# MCXC444 register map
Vendor: NXP Semiconductors; Series: MCX; File version: 1.6
CPU: CM0PLUS r0p0, little endian, no MPU, no FPU, VTOR, 2 interrupt priority bits
Registers are 32-bit, read-write, reset 0x0 unless marked. A register's access mark holds for its fields unless they carry their own. Offsets are from the block's base; [hi:lo] are bit positions.

## SystemControl — System Control Block
Base 0xE000E000; register names take the prefix SCB_
0x08 ACTLR ro — Auxiliary Control Register,
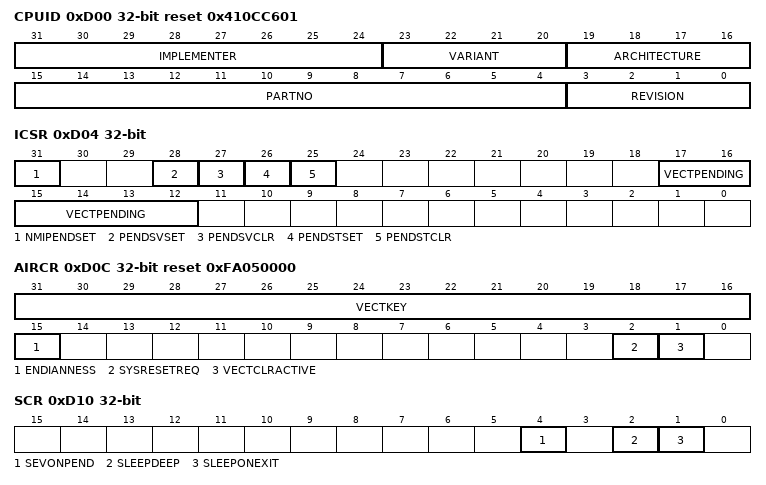
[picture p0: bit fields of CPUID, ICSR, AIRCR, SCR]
0xD00 CPUID ro reset 0x410CC601 — CPUID Base Register
  [31:24] IMPLEMENTER — Implementer code
  [23:20] VARIANT — Major revision number n in the npm revision status
  [19:16] ARCHITECTURE — Indicates the architecture
  [15:4] PARTNO — Indicates part number
  [3:0] REVISION — Minor revision number m in the rnpm revision status
0xD04 ICSR — Interrupt Control and State Register
  [31] NMIPENDSET — NMI set-pending bit
    0=b0 (write: no effect; read: NMI exception is not pending); 1=b1 (write: changes NMI exception state to pending; read: NMI exception is pending)
  [28] PENDSVSET — PendSV set-pending bit
    0=b0 (write: no effect; read: PendSV exception is not pending); 1=b1 (write: changes PendSV exception state to pending; read: PendSV exception is pending)
  [27] PENDSVCLR wo — PendSV clear-pending bit
    0=b0 (no effect); 1=b1 (removes the pending state from the PendSV exception)
  [26] PENDSTSET — SysTick exception set-pending bit
    0=b0 (write: no effect; read: SysTick exception is not pending); 1=b1 (write: changes SysTick exception state to pending; read: SysTick exception is pending)
  [25] PENDSTCLR wo — SysTick exception clear-pending bit
    0=b0 (no effect); 1=b1 (removes the pending state from the SysTick exception)
  [17:12] VECTPENDING ro — Exception number of the highest priority pending enabled exception
0xD08 VTOR — Vector Table Offset Register
  [31:7] TBLOFF — Vector table base offset
0xD0C AIRCR reset 0xFA050000 — Application Interrupt and Reset Control Register
  [31:16] VECTKEY — Register key
  [15] ENDIANNESS ro — Data endianness bit
    0=b0 (Little-endian); 1=b1 (Big-endian)
  [2] SYSRESETREQ wo — System reset request
    0=b0 (no system reset request); 1=b1 (asserts a signal to the outer system that requests a reset)
  [1] VECTCLRACTIVE wo — Reserved for Debug use
0xD10 SCR — System Control Register
  [4] SEVONPEND — Send Event on Pending bit
    0=b0 (only enabled interrupts or events can wakeup the processor, disabled interrupts are excluded); 1=b1 (enabled events and all interrupts, including disabled interrupts, can wakeup the processor)
  [2] SLEEPDEEP — Controls whether the processor uses sleep or deep sleep as its low power mode
    0=b0 (sleep); 1=b1 (deep sleep)
  [1] SLEEPONEXIT — Indicates sleep-on-exit when returning from Handler mode to Thread mode
    0=b0 (do not sleep when returning to Thread mode); 1=b1 (enter sleep, or deep sleep, on return from an ISR)
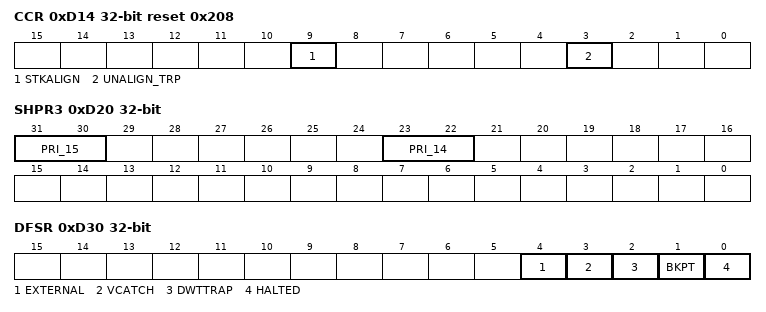
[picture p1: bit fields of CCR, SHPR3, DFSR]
0xD14 CCR ro reset 0x208 — Configuration and Control Register
  [9] STKALIGN — Indicates stack alignment on exception entry
  [3] UNALIGN_TRP — Always reads as one, indicates that all unaligned accesses generate a HardFault
0xD1C SHPR2 — System Handler Priority Register 2
  [31:30] PRI_11 — Priority of system handler 11, SVCall
0xD20 SHPR3 — System Handler Priority Register 3
  [31:30] PRI_15 — Priority of system handler 15, SysTick exception
  [23:22] PRI_14 — Priority of system handler 14, PendSV
0xD24 SHCSR — System Handler Control and State Register
  [15] SVCALLPENDED
    0=b0 (exception is not pending); 1=b1 (exception is pending)
0xD30 DFSR — Debug Fault Status Register
  [4] EXTERNAL
    0=b0 (No EDBGRQ debug event); 1=b1 (EDBGRQ debug event)
  [3] VCATCH
    0=b0 (No Vector catch triggered); 1=b1 (Vector catch triggered)
  [2] DWTTRAP
    0=b0 (No current debug events generated by the DWT); 1=b1 (At least one current debug event generated by the DWT)
  [1] BKPT
    0=b0 (No current breakpoint debug event); 1=b1 (At least one current breakpoint debug event)
  [0] HALTED
    0=b0 (No active halt request debug event); 1=b1 (Halt request debug event active)
